AUTOSAR XML (schema 4-2-2)
package /ComponentTypes
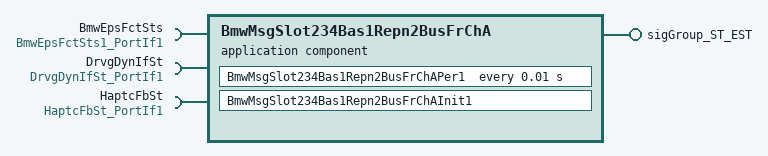
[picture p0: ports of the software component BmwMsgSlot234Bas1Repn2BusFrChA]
  application sw component type BmwMsgSlot234Bas1Repn2BusFrChA
    provide port sigGroup_ST_EST: nonqueued-sender-com-spec{data-element=sigGroup_ST_EST, uses-end-to-end-protection=true, init-value=fields=[QU_SER_STMOM_DV_ACT:128, QU_FN_VIB_EPS:14, ST_EST_dummy_16_23:0, ALIV_ST_EST_FTAX:15, CRC_ST_EST_FTAX:0, QU_FN_EST:128]}, provided-interface=sigGroup_ST_EST
    require port BmwEpsFctSts: nonqueued-receiver-com-spec{data-element=Val, filter=data-filter-type=ALWAYS, init-value=128}, required-interface=BmwEpsFctSts1_PortIf1
    require port DrvgDynIfSt: nonqueued-receiver-com-spec{data-element=Val, filter=data-filter-type=ALWAYS, init-value=128}, required-interface=DrvgDynIfSt_PortIf1
    require port HaptcFbSt: nonqueued-receiver-com-spec{data-element=Val, filter=data-filter-type=ALWAYS, init-value=14}, required-interface=HaptcFbSt_PortIf1
    behavior BmwMsgSlot234Bas1Repn2BusFrChA_InternalBehavior
      ar-typed-per-instance-memorys:
        6 x data, all with sw-calibration-access=READ-ONLY:
          BmwEpsFctStsPrev: type=BmwEpsFctSts1
          BurstModCntr: type=uint8
          CycCntr: type=uint8
          DrvgDynIfStPrev: type=DrvgDynIfSt1
          HaptcFbStPrev: type=HaptcFbSt1
          PerdCntr: type=uint8
      init event BmwMsgSlot234Bas1Repn2BusFrChA_InitEvent: start-on-event=BmwMsgSlot234Bas1Repn2BusFrChAInit1
      timing event TMT_BmwMsgSlot234Bas1Repn2BusFrChAPer1: start-on-event=BmwMsgSlot234Bas1Repn2BusFrChAPer1, period=0.01
      port-api-options:
        enable-take-address=false, error-handling=NO-TRANSFORMER-ERROR-HANDLING, indirect-api=false, port=HaptcFbSt
        enable-take-address=false, error-handling=NO-TRANSFORMER-ERROR-HANDLING, indirect-api=false, port=sigGroup_ST_EST
      runnable BmwMsgSlot234Bas1Repn2BusFrChAInit1
      runnable BmwMsgSlot234Bas1Repn2BusFrChAPer1
        data-receive-point-by-arguments:
          access REC_BmwEpsFctSts_Val: accessed-variable=BmwEpsFctSts.Val
          access REC_DrvgDynIfSt_PortIf1_Val: accessed-variable=DrvgDynIfSt.Val
          access REC_HaptcFbSt_PortIf1_Val: accessed-variable=HaptcFbSt.Val
        data-send-points:
          access SEND_sigGroup_ST_EST_sigGroup_ST_EST: accessed-variable=sigGroup_ST_EST.sigGroup_ST_EST
  swc implementation BmwMsgSlot234Bas1Repn2BusFrChA_Implementation: behavior=BmwMsgSlot234Bas1Repn2BusFrChA_InternalBehavior
    code-descriptors:
      code Default: artifact-descriptors=autosar-engineering-object={short-label=Default, category=SWSRC}
